# CTRL_MODULE_CORE register map
Vendor: Texas Instruments
Registers are 32-bit, access per field, reset 0x0 unless marked. A register's access mark holds for its fields unless they carry their own. Offsets are as the file gives them; [hi:lo] are bit positions; 'fields as' and 'values as' point back to an identical list.

## CTRL_MODULE_CORE (part 6 of 12)
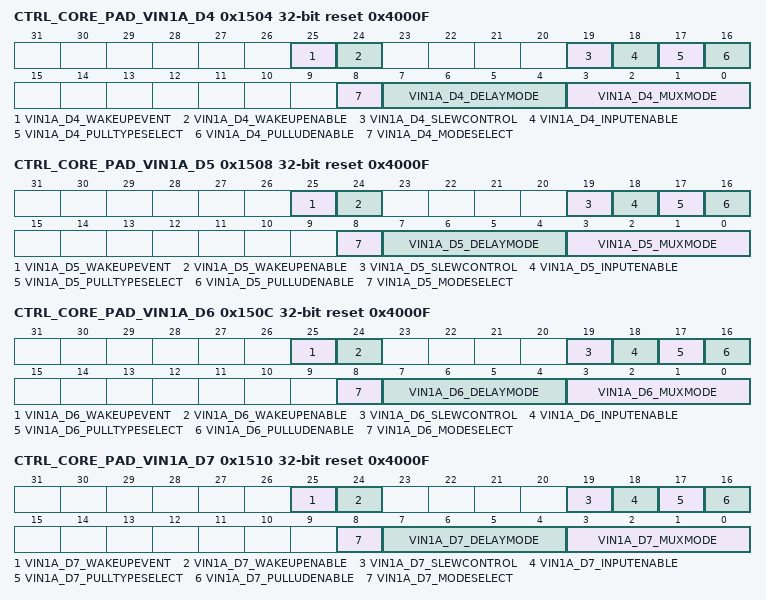
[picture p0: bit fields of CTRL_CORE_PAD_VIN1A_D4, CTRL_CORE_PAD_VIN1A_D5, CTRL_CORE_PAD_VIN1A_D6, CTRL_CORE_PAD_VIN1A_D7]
0x1504 CTRL_CORE_PAD_VIN1A_D4 reset 0x4000F
  [25] VIN1A_D4_WAKEUPEVENT ro
    0=NOWAKEUP (No wakeup event detected); 1=WAKEUP (Wakeup event detected)
  [24] VIN1A_D4_WAKEUPENABLE rw
    0=DISABLE (Wakeup is disabled); 1=ENABLE (Wakeup is enabled)
  [19] VIN1A_D4_SLEWCONTROL rw
    0=FAST_SLEW (Fast slew is selected); 1=SLOW_SLEW (Slow slew is selected)
  [18] VIN1A_D4_INPUTENABLE rw
    0=DISABLE (Receive mode is disabled); 1=ENABLE (Receive mode is enabled)
  [17] VIN1A_D4_PULLTYPESELECT rw
    0=PULL_DOWN (Pull Down is selected); 1=PULL_UP (Pull Up is selected)
  [16] VIN1A_D4_PULLUDENABLE rw
    0=ENABLE (Enables weak Pull Up/Down); 1=DISABLE (Disables weak Pull Up/Down)
  [8] VIN1A_D4_MODESELECT rw — Selects between the Default IO Timing Mode and a Virtual or Manual IO Timing Mode. Refer to the device Data Manual for definition of the required settings for a given mode of operation. When this bit is 0b1, a Virtual IO Timing Mode can be selected via the DELAYMODE field of this register, as described in, Virtual IO Timing Modes. Manual IO Timing Modes are selected via the procedure described in , Manual IO Timing Modes.
    0=MUX_MODE (Default IO Timing Mode is used); 1=DELAY_MODE (A Virtual or Manual IO Timing Mode is used)
  [7:4] VIN1A_D4_DELAYMODE rw — This bit field selects the Virtual Timing Mode used when the MODESELECT bit is set to 0b1. See, Virtual IO Timing Modes for details.
  [3:0] VIN1A_D4_MUXMODE rw
    0=VIN1A_D4; 3=VOUT3_D3; 4=VOUT3_D19; 10=EHRPWM1_SYNCI; 12=PR1_PRU0_GPI1; 13=PR1_PRU0_GPO1; 14=GPIO3_8; 15=DRIVER OFF
0x1508 CTRL_CORE_PAD_VIN1A_D5 reset 0x4000F
  [25] VIN1A_D5_WAKEUPEVENT ro
    values as CTRL_CORE_PAD_VIN1A_D4.VIN1A_D4_WAKEUPEVENT
  [24] VIN1A_D5_WAKEUPENABLE rw
    0=DISABLE (Wakeup is disabled); 1=ENABLE (Wakeup is enabled)
  [19] VIN1A_D5_SLEWCONTROL rw
    values as CTRL_CORE_PAD_VIN1A_D4.VIN1A_D4_SLEWCONTROL
  [18] VIN1A_D5_INPUTENABLE rw
    values as CTRL_CORE_PAD_VIN1A_D4.VIN1A_D4_INPUTENABLE
  [17] VIN1A_D5_PULLTYPESELECT rw
    values as CTRL_CORE_PAD_VIN1A_D4.VIN1A_D4_PULLTYPESELECT
  [16] VIN1A_D5_PULLUDENABLE rw
    values as CTRL_CORE_PAD_VIN1A_D4.VIN1A_D4_PULLUDENABLE
  [8] VIN1A_D5_MODESELECT rw — Selects between the Default IO Timing Mode and a Virtual or Manual IO Timing Mode. Refer to the device Data Manual for definition of the required settings for a given mode of operation. When this bit is 0b1, a Virtual IO Timing Mode can be selected via the DELAYMODE field of this register, as described in, Virtual IO Timing Modes. Manual IO Timing Modes are selected via the procedure described in , Manual IO Timing Modes.
    values as CTRL_CORE_PAD_VIN1A_D4.VIN1A_D4_MODESELECT
  [7:4] VIN1A_D5_DELAYMODE rw — This bit field selects the Virtual Timing Mode used when the MODESELECT bit is set to 0b1. See, Virtual IO Timing Modes for details.
  [3:0] VIN1A_D5_MUXMODE rw
    0=VIN1A_D5; 3=VOUT3_D2; 4=VOUT3_D18; 10=EHRPWM1_SYNCO; 12=PR1_PRU0_GPI2; 13=PR1_PRU0_GPO2; 14=GPIO3_9; 15=DRIVER OFF
0x150C CTRL_CORE_PAD_VIN1A_D6 reset 0x4000F
  [25] VIN1A_D6_WAKEUPEVENT ro
    values as CTRL_CORE_PAD_VIN1A_D4.VIN1A_D4_WAKEUPEVENT
  [24] VIN1A_D6_WAKEUPENABLE rw
    0=DISABLE (Wakeup is disabled); 1=ENABLE (Wakeup is enabled)
  [19] VIN1A_D6_SLEWCONTROL rw
    values as CTRL_CORE_PAD_VIN1A_D4.VIN1A_D4_SLEWCONTROL
  [18] VIN1A_D6_INPUTENABLE rw
    values as CTRL_CORE_PAD_VIN1A_D4.VIN1A_D4_INPUTENABLE
  [17] VIN1A_D6_PULLTYPESELECT rw
    values as CTRL_CORE_PAD_VIN1A_D4.VIN1A_D4_PULLTYPESELECT
  [16] VIN1A_D6_PULLUDENABLE rw
    values as CTRL_CORE_PAD_VIN1A_D4.VIN1A_D4_PULLUDENABLE
  [8] VIN1A_D6_MODESELECT rw — Selects between the Default IO Timing Mode and a Virtual or Manual IO Timing Mode. Refer to the device Data Manual for definition of the required settings for a given mode of operation. When this bit is 0b1, a Virtual IO Timing Mode can be selected via the DELAYMODE field of this register, as described in, Virtual IO Timing Modes. Manual IO Timing Modes are selected via the procedure described in , Manual IO Timing Modes.
    values as CTRL_CORE_PAD_VIN1A_D4.VIN1A_D4_MODESELECT
  [7:4] VIN1A_D6_DELAYMODE rw — This bit field selects the Virtual Timing Mode used when the MODESELECT bit is set to 0b1. See, Virtual IO Timing Modes for details.
  [3:0] VIN1A_D6_MUXMODE rw
    0=VIN1A_D6; 3=VOUT3_D1; 4=VOUT3_D17; 10=EQEP2A_IN; 12=PR1_PRU0_GPI3; 13=PR1_PRU0_GPO3; 14=GPIO3_10; 15=DRIVER OFF
0x1510 CTRL_CORE_PAD_VIN1A_D7 reset 0x4000F
  [25] VIN1A_D7_WAKEUPEVENT ro
    values as CTRL_CORE_PAD_VIN1A_D4.VIN1A_D4_WAKEUPEVENT
  [24] VIN1A_D7_WAKEUPENABLE rw
    0=DISABLE (Wakeup is disabled); 1=ENABLE (Wakeup is enabled)
  [19] VIN1A_D7_SLEWCONTROL rw
    values as CTRL_CORE_PAD_VIN1A_D4.VIN1A_D4_SLEWCONTROL
  [18] VIN1A_D7_INPUTENABLE rw
    values as CTRL_CORE_PAD_VIN1A_D4.VIN1A_D4_INPUTENABLE
  [17] VIN1A_D7_PULLTYPESELECT rw
    values as CTRL_CORE_PAD_VIN1A_D4.VIN1A_D4_PULLTYPESELECT
  [16] VIN1A_D7_PULLUDENABLE rw
    values as CTRL_CORE_PAD_VIN1A_D4.VIN1A_D4_PULLUDENABLE
  [8] VIN1A_D7_MODESELECT rw — Selects between the Default IO Timing Mode and a Virtual or Manual IO Timing Mode. Refer to the device Data Manual for definition of the required settings for a given mode of operation. When this bit is 0b1, a Virtual IO Timing Mode can be selected via the DELAYMODE field of this register, as described in, Virtual IO Timing Modes. Manual IO Timing Modes are selected via the procedure described in , Manual IO Timing Modes.
    values as CTRL_CORE_PAD_VIN1A_D4.VIN1A_D4_MODESELECT
  [7:4] VIN1A_D7_DELAYMODE rw — This bit field selects the Virtual Timing Mode used when the MODESELECT bit is set to 0b1. See, Virtual IO Timing Modes for details.
  [3:0] VIN1A_D7_MUXMODE rw
    0=VIN1A_D7; 3=VOUT3_D0; 4=VOUT3_D16; 10=EQEP2B_IN; 12=PR1_PRU0_GPI4; 13=PR1_PRU0_GPO4; 14=GPIO3_11; 15=DRIVER OFF
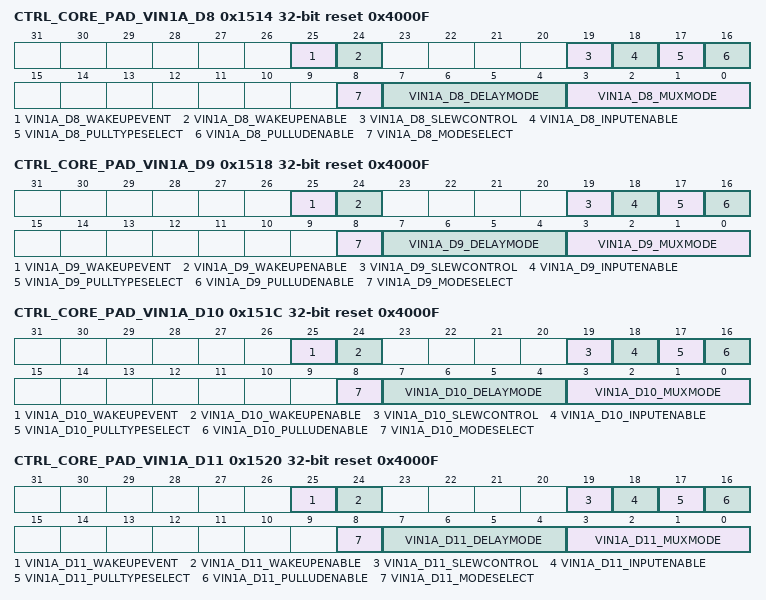
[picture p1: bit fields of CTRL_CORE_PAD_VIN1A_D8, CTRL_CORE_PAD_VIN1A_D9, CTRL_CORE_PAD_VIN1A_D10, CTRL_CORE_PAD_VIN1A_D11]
0x1514 CTRL_CORE_PAD_VIN1A_D8 reset 0x4000F
  [25] VIN1A_D8_WAKEUPEVENT ro
    values as CTRL_CORE_PAD_VIN1A_D4.VIN1A_D4_WAKEUPEVENT
  [24] VIN1A_D8_WAKEUPENABLE rw
    0=DISABLE (Wakeup is disabled); 1=ENABLE (Wakeup is enabled)
  [19] VIN1A_D8_SLEWCONTROL rw
    values as CTRL_CORE_PAD_VIN1A_D4.VIN1A_D4_SLEWCONTROL
  [18] VIN1A_D8_INPUTENABLE rw
    values as CTRL_CORE_PAD_VIN1A_D4.VIN1A_D4_INPUTENABLE
  [17] VIN1A_D8_PULLTYPESELECT rw
    values as CTRL_CORE_PAD_VIN1A_D4.VIN1A_D4_PULLTYPESELECT
  [16] VIN1A_D8_PULLUDENABLE rw
    values as CTRL_CORE_PAD_VIN1A_D4.VIN1A_D4_PULLUDENABLE
  [8] VIN1A_D8_MODESELECT rw — Selects between the Default IO Timing Mode and a Virtual or Manual IO Timing Mode. Refer to the device Data Manual for definition of the required settings for a given mode of operation. When this bit is 0b1, a Virtual IO Timing Mode can be selected via the DELAYMODE field of this register, as described in, Virtual IO Timing Modes. Manual IO Timing Modes are selected via the procedure described in , Manual IO Timing Modes.
    values as CTRL_CORE_PAD_VIN1A_D4.VIN1A_D4_MODESELECT
  [7:4] VIN1A_D8_DELAYMODE rw — This bit field selects the Virtual Timing Mode used when the MODESELECT bit is set to 0b1. See, Virtual IO Timing Modes for details.
  [3:0] VIN1A_D8_MUXMODE rw
    0=VIN1A_D8; 1=VIN1B_D7; 4=VOUT3_D15; 9=KBD_ROW2; 10=EQEP2_INDEX; 12=PR1_PRU0_GPI5; 13=PR1_PRU0_GPO5; 14=GPIO3_12; 15=DRIVER OFF
0x1518 CTRL_CORE_PAD_VIN1A_D9 reset 0x4000F
  [25] VIN1A_D9_WAKEUPEVENT ro
    values as CTRL_CORE_PAD_VIN1A_D4.VIN1A_D4_WAKEUPEVENT
  [24] VIN1A_D9_WAKEUPENABLE rw
    0=DISABLE (Wakeup is disabled); 1=ENABLE (Wakeup is enabled)
  [19] VIN1A_D9_SLEWCONTROL rw
    values as CTRL_CORE_PAD_VIN1A_D4.VIN1A_D4_SLEWCONTROL
  [18] VIN1A_D9_INPUTENABLE rw
    values as CTRL_CORE_PAD_VIN1A_D4.VIN1A_D4_INPUTENABLE
  [17] VIN1A_D9_PULLTYPESELECT rw
    values as CTRL_CORE_PAD_VIN1A_D4.VIN1A_D4_PULLTYPESELECT
  [16] VIN1A_D9_PULLUDENABLE rw
    values as CTRL_CORE_PAD_VIN1A_D4.VIN1A_D4_PULLUDENABLE
  [8] VIN1A_D9_MODESELECT rw — Selects between the Default IO Timing Mode and a Virtual or Manual IO Timing Mode. Refer to the device Data Manual for definition of the required settings for a given mode of operation. When this bit is 0b1, a Virtual IO Timing Mode can be selected via the DELAYMODE field of this register, as described in, Virtual IO Timing Modes. Manual IO Timing Modes are selected via the procedure described in , Manual IO Timing Modes.
    values as CTRL_CORE_PAD_VIN1A_D4.VIN1A_D4_MODESELECT
  [7:4] VIN1A_D9_DELAYMODE rw — This bit field selects the Virtual Timing Mode used when the MODESELECT bit is set to 0b1. See, Virtual IO Timing Modes for details.
  [3:0] VIN1A_D9_MUXMODE rw
    0=VIN1A_D9; 1=VIN1B_D6; 4=VOUT3_D14; 9=KBD_ROW3; 10=EQEP2_STROBE; 12=PR1_PRU0_GPI6; 13=PR1_PRU0_GPO6; 14=GPIO3_13; 15=DRIVER OFF
0x151C CTRL_CORE_PAD_VIN1A_D10 reset 0x4000F
  [25] VIN1A_D10_WAKEUPEVENT ro
    values as CTRL_CORE_PAD_VIN1A_D4.VIN1A_D4_WAKEUPEVENT
  [24] VIN1A_D10_WAKEUPENABLE rw
    0=DISABLE (Wakeup is disabled); 1=ENABLE (Wakeup is enabled)
  [19] VIN1A_D10_SLEWCONTROL rw
    values as CTRL_CORE_PAD_VIN1A_D4.VIN1A_D4_SLEWCONTROL
  [18] VIN1A_D10_INPUTENABLE rw
    values as CTRL_CORE_PAD_VIN1A_D4.VIN1A_D4_INPUTENABLE
  [17] VIN1A_D10_PULLTYPESELECT rw
    values as CTRL_CORE_PAD_VIN1A_D4.VIN1A_D4_PULLTYPESELECT
  [16] VIN1A_D10_PULLUDENABLE rw
    values as CTRL_CORE_PAD_VIN1A_D4.VIN1A_D4_PULLUDENABLE
  [8] VIN1A_D10_MODESELECT rw — Selects between the Default IO Timing Mode and a Virtual or Manual IO Timing Mode. Refer to the device Data Manual for definition of the required settings for a given mode of operation. When this bit is 0b1, a Virtual IO Timing Mode can be selected via the DELAYMODE field of this register, as described in, Virtual IO Timing Modes. Manual IO Timing Modes are selected via the procedure described in , Manual IO Timing Modes.
    values as CTRL_CORE_PAD_VIN1A_D4.VIN1A_D4_MODESELECT
  [7:4] VIN1A_D10_DELAYMODE rw — This bit field selects the Virtual Timing Mode used when the MODESELECT bit is set to 0b1. See, Virtual IO Timing Modes for details.
  [3:0] VIN1A_D10_MUXMODE rw
    0=VIN1A_D10; 1=VIN1B_D5; 4=VOUT3_D13; 9=KBD_ROW4; 10=PR1_EDC_LATCH0_IN; 12=PR1_PRU0_GPI7; 13=PR1_PRU0_GPO7; 14=GPIO3_14; 15=DRIVER OFF
0x1520 CTRL_CORE_PAD_VIN1A_D11 reset 0x4000F
  [25] VIN1A_D11_WAKEUPEVENT ro
    values as CTRL_CORE_PAD_VIN1A_D4.VIN1A_D4_WAKEUPEVENT
  [24] VIN1A_D11_WAKEUPENABLE rw
    0=DISABLE (Wakeup is disabled); 1=ENABLE (Wakeup is enabled)
  [19] VIN1A_D11_SLEWCONTROL rw
    values as CTRL_CORE_PAD_VIN1A_D4.VIN1A_D4_SLEWCONTROL
  [18] VIN1A_D11_INPUTENABLE rw
    values as CTRL_CORE_PAD_VIN1A_D4.VIN1A_D4_INPUTENABLE
  [17] VIN1A_D11_PULLTYPESELECT rw
    values as CTRL_CORE_PAD_VIN1A_D4.VIN1A_D4_PULLTYPESELECT
  [16] VIN1A_D11_PULLUDENABLE rw
    values as CTRL_CORE_PAD_VIN1A_D4.VIN1A_D4_PULLUDENABLE
  [8] VIN1A_D11_MODESELECT rw — Selects between the Default IO Timing Mode and a Virtual or Manual IO Timing Mode. Refer to the device Data Manual for definition of the required settings for a given mode of operation. When this bit is 0b1, a Virtual IO Timing Mode can be selected via the DELAYMODE field of this register, as described in, Virtual IO Timing Modes. Manual IO Timing Modes are selected via the procedure described in , Manual IO Timing Modes.
    values as CTRL_CORE_PAD_VIN1A_D4.VIN1A_D4_MODESELECT
  [7:4] VIN1A_D11_DELAYMODE rw — This bit field selects the Virtual Timing Mode used when the MODESELECT bit is set to 0b1. See, Virtual IO Timing Modes for details.
  [3:0] VIN1A_D11_MUXMODE rw
    0=VIN1A_D11; 1=VIN1B_D4; 4=VOUT3_D12; 5=GPMC_A23; 9=KBD_ROW5; 10=PR1_EDC_LATCH1_IN; 12=PR1_PRU0_GPI8; 13=PR1_PRU0_GPO8; 14=GPIO3_15; 15=DRIVER OFF
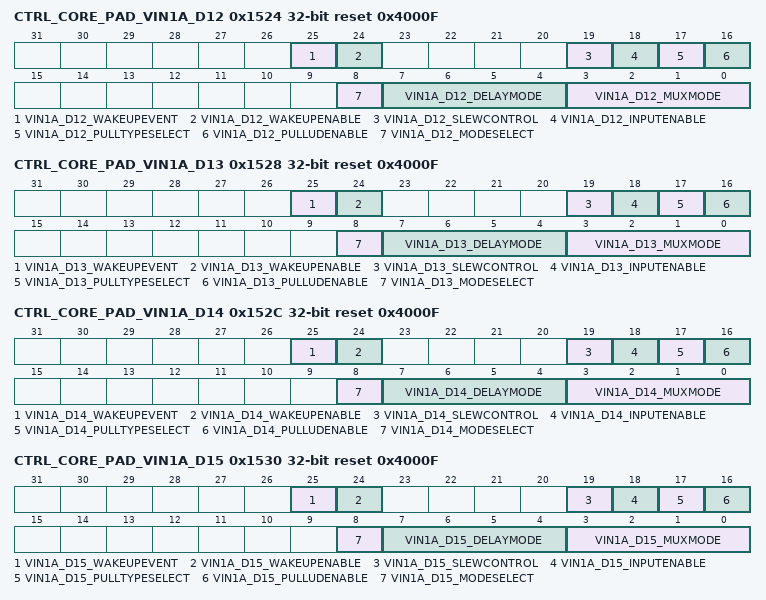
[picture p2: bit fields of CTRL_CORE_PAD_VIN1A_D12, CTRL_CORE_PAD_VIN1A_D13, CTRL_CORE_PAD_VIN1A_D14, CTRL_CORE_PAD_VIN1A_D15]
0x1524 CTRL_CORE_PAD_VIN1A_D12 reset 0x4000F
  [25] VIN1A_D12_WAKEUPEVENT ro
    values as CTRL_CORE_PAD_VIN1A_D4.VIN1A_D4_WAKEUPEVENT
  [24] VIN1A_D12_WAKEUPENABLE rw
    0=DISABLE (Wakeup is disabled); 1=ENABLE (Wakeup is enabled)
  [19] VIN1A_D12_SLEWCONTROL rw
    values as CTRL_CORE_PAD_VIN1A_D4.VIN1A_D4_SLEWCONTROL
  [18] VIN1A_D12_INPUTENABLE rw
    values as CTRL_CORE_PAD_VIN1A_D4.VIN1A_D4_INPUTENABLE
  [17] VIN1A_D12_PULLTYPESELECT rw
    values as CTRL_CORE_PAD_VIN1A_D4.VIN1A_D4_PULLTYPESELECT
  [16] VIN1A_D12_PULLUDENABLE rw
    values as CTRL_CORE_PAD_VIN1A_D4.VIN1A_D4_PULLUDENABLE
  [8] VIN1A_D12_MODESELECT rw — Selects between the Default IO Timing Mode and a Virtual or Manual IO Timing Mode. Refer to the device Data Manual for definition of the required settings for a given mode of operation. When this bit is 0b1, a Virtual IO Timing Mode can be selected via the DELAYMODE field of this register, as described in, Virtual IO Timing Modes. Manual IO Timing Modes are selected via the procedure described in , Manual IO Timing Modes.
    values as CTRL_CORE_PAD_VIN1A_D4.VIN1A_D4_MODESELECT
  [7:4] VIN1A_D12_DELAYMODE rw — This bit field selects the Virtual Timing Mode used when the MODESELECT bit is set to 0b1. See, Virtual IO Timing Modes for details.
  [3:0] VIN1A_D12_MUXMODE rw
    0=VIN1A_D12; 1=VIN1B_D3; 4=VOUT3_D11; 5=GPMC_A24; 9=KBD_ROW6; 10=PR1_EDC_SYNC0_OUT; 12=PR1_PRU0_GPI9; 13=PR1_PRU0_GPO9; 14=GPIO3_16; 15=DRIVER OFF
0x1528 CTRL_CORE_PAD_VIN1A_D13 reset 0x4000F
  [25] VIN1A_D13_WAKEUPEVENT ro
    values as CTRL_CORE_PAD_VIN1A_D4.VIN1A_D4_WAKEUPEVENT
  [24] VIN1A_D13_WAKEUPENABLE rw
    0=DISABLE (Wakeup is disabled); 1=ENABLE (Wakeup is enabled)
  [19] VIN1A_D13_SLEWCONTROL rw
    values as CTRL_CORE_PAD_VIN1A_D4.VIN1A_D4_SLEWCONTROL
  [18] VIN1A_D13_INPUTENABLE rw
    values as CTRL_CORE_PAD_VIN1A_D4.VIN1A_D4_INPUTENABLE
  [17] VIN1A_D13_PULLTYPESELECT rw
    values as CTRL_CORE_PAD_VIN1A_D4.VIN1A_D4_PULLTYPESELECT
  [16] VIN1A_D13_PULLUDENABLE rw
    values as CTRL_CORE_PAD_VIN1A_D4.VIN1A_D4_PULLUDENABLE
  [8] VIN1A_D13_MODESELECT rw — Selects between the Default IO Timing Mode and a Virtual or Manual IO Timing Mode. Refer to the device Data Manual for definition of the required settings for a given mode of operation. When this bit is 0b1, a Virtual IO Timing Mode can be selected via the DELAYMODE field of this register, as described in, Virtual IO Timing Modes. Manual IO Timing Modes are selected via the procedure described in , Manual IO Timing Modes.
    values as CTRL_CORE_PAD_VIN1A_D4.VIN1A_D4_MODESELECT
  [7:4] VIN1A_D13_DELAYMODE rw — This bit field selects the Virtual Timing Mode used when the MODESELECT bit is set to 0b1. See, Virtual IO Timing Modes for details.
  [3:0] VIN1A_D13_MUXMODE rw
    0=VIN1A_D13; 1=VIN1B_D2; 4=VOUT3_D10; 5=GPMC_A25; 9=KBD_ROW7; 10=PR1_EDC_SYNC1_OUT; 12=PR1_PRU0_GPI10; 13=PR1_PRU0_GPO10; 14=GPIO3_17; 15=DRIVER OFF
0x152C CTRL_CORE_PAD_VIN1A_D14 reset 0x4000F
  [25] VIN1A_D14_WAKEUPEVENT ro
    values as CTRL_CORE_PAD_VIN1A_D4.VIN1A_D4_WAKEUPEVENT
  [24] VIN1A_D14_WAKEUPENABLE rw
    0=DISABLE (Wakeup is disabled); 1=ENABLE (Wakeup is enabled)
  [19] VIN1A_D14_SLEWCONTROL rw
    values as CTRL_CORE_PAD_VIN1A_D4.VIN1A_D4_SLEWCONTROL
  [18] VIN1A_D14_INPUTENABLE rw
    values as CTRL_CORE_PAD_VIN1A_D4.VIN1A_D4_INPUTENABLE
  [17] VIN1A_D14_PULLTYPESELECT rw
    values as CTRL_CORE_PAD_VIN1A_D4.VIN1A_D4_PULLTYPESELECT
  [16] VIN1A_D14_PULLUDENABLE rw
    values as CTRL_CORE_PAD_VIN1A_D4.VIN1A_D4_PULLUDENABLE
  [8] VIN1A_D14_MODESELECT rw — Selects between the Default IO Timing Mode and a Virtual or Manual IO Timing Mode. Refer to the device Data Manual for definition of the required settings for a given mode of operation. When this bit is 0b1, a Virtual IO Timing Mode can be selected via the DELAYMODE field of this register, as described in, Virtual IO Timing Modes. Manual IO Timing Modes are selected via the procedure described in , Manual IO Timing Modes.
    values as CTRL_CORE_PAD_VIN1A_D4.VIN1A_D4_MODESELECT
  [7:4] VIN1A_D14_DELAYMODE rw — This bit field selects the Virtual Timing Mode used when the MODESELECT bit is set to 0b1. See, Virtual IO Timing Modes for details.
  [3:0] VIN1A_D14_MUXMODE rw
    0=VIN1A_D14; 1=VIN1B_D1; 4=VOUT3_D9; 5=GPMC_A26; 9=KBD_ROW8; 10=PR1_EDIO_LATCH_IN; 12=PR1_PRU0_GPI11; 13=PR1_PRU0_GPO11; 14=GPIO3_18; 15=DRIVER OFF
0x1530 CTRL_CORE_PAD_VIN1A_D15 reset 0x4000F
  [25] VIN1A_D15_WAKEUPEVENT ro
    values as CTRL_CORE_PAD_VIN1A_D4.VIN1A_D4_WAKEUPEVENT
  [24] VIN1A_D15_WAKEUPENABLE rw
    0=DISABLE (Wakeup is disabled); 1=ENABLE (Wakeup is enabled)
  [19] VIN1A_D15_SLEWCONTROL rw
    values as CTRL_CORE_PAD_VIN1A_D4.VIN1A_D4_SLEWCONTROL
  [18] VIN1A_D15_INPUTENABLE rw
    values as CTRL_CORE_PAD_VIN1A_D4.VIN1A_D4_INPUTENABLE
  [17] VIN1A_D15_PULLTYPESELECT rw
    values as CTRL_CORE_PAD_VIN1A_D4.VIN1A_D4_PULLTYPESELECT
  [16] VIN1A_D15_PULLUDENABLE rw
    values as CTRL_CORE_PAD_VIN1A_D4.VIN1A_D4_PULLUDENABLE
  [8] VIN1A_D15_MODESELECT rw — Selects between the Default IO Timing Mode and a Virtual or Manual IO Timing Mode. Refer to the device Data Manual for definition of the required settings for a given mode of operation. When this bit is 0b1, a Virtual IO Timing Mode can be selected via the DELAYMODE field of this register, as described in, Virtual IO Timing Modes. Manual IO Timing Modes are selected via the procedure described in , Manual IO Timing Modes.
    values as CTRL_CORE_PAD_VIN1A_D4.VIN1A_D4_MODESELECT
  [7:4] VIN1A_D15_DELAYMODE rw — This bit field selects the Virtual Timing Mode used when the MODESELECT bit is set to 0b1. See, Virtual IO Timing Modes for details.
  [3:0] VIN1A_D15_MUXMODE rw
    0=VIN1A_D15; 1=VIN1B_D0; 4=VOUT3_D8; 5=GPMC_A27; 9=KBD_COL0; 10=PR1_EDIO_SOF; 12=PR1_PRU0_GPI12; 13=PR1_PRU0_GPO12; 14=GPIO3_19; 15=DRIVER OFF
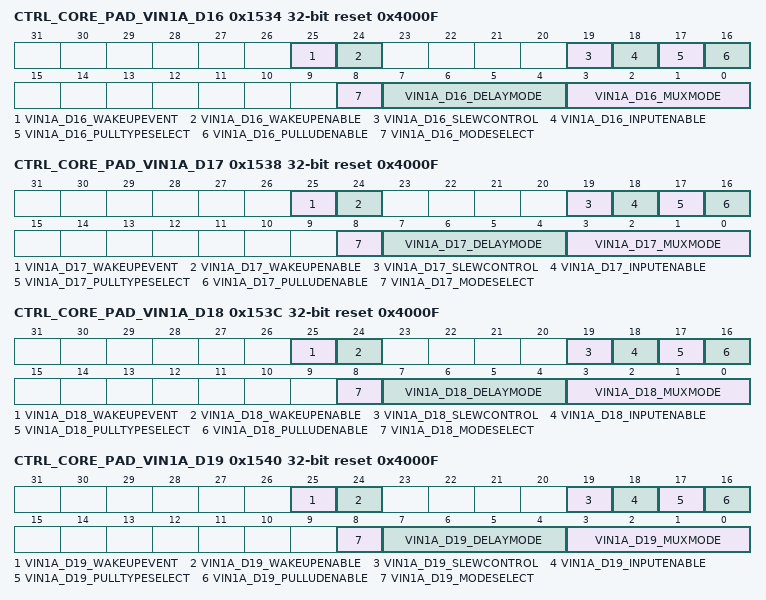
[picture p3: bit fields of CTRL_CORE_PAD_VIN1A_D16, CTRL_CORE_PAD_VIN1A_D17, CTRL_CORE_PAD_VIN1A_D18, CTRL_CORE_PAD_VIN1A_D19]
0x1534 CTRL_CORE_PAD_VIN1A_D16 reset 0x4000F
  [25] VIN1A_D16_WAKEUPEVENT ro
    values as CTRL_CORE_PAD_VIN1A_D4.VIN1A_D4_WAKEUPEVENT
  [24] VIN1A_D16_WAKEUPENABLE rw
    0=DISABLE (Wakeup is disabled); 1=ENABLE (Wakeup is enabled)
  [19] VIN1A_D16_SLEWCONTROL rw
    values as CTRL_CORE_PAD_VIN1A_D4.VIN1A_D4_SLEWCONTROL
  [18] VIN1A_D16_INPUTENABLE rw
    values as CTRL_CORE_PAD_VIN1A_D4.VIN1A_D4_INPUTENABLE
  [17] VIN1A_D16_PULLTYPESELECT rw
    values as CTRL_CORE_PAD_VIN1A_D4.VIN1A_D4_PULLTYPESELECT
  [16] VIN1A_D16_PULLUDENABLE rw
    values as CTRL_CORE_PAD_VIN1A_D4.VIN1A_D4_PULLUDENABLE
  [8] VIN1A_D16_MODESELECT rw — Selects between the Default IO Timing Mode and a Virtual or Manual IO Timing Mode. Refer to the device Data Manual for definition of the required settings for a given mode of operation. When this bit is 0b1, a Virtual IO Timing Mode can be selected via the DELAYMODE field of this register, as described in, Virtual IO Timing Modes. Manual IO Timing Modes are selected via the procedure described in , Manual IO Timing Modes.
    values as CTRL_CORE_PAD_VIN1A_D4.VIN1A_D4_MODESELECT
  [7:4] VIN1A_D16_DELAYMODE rw — This bit field selects the Virtual Timing Mode used when the MODESELECT bit is set to 0b1. See, Virtual IO Timing Modes for details.
  [3:0] VIN1A_D16_MUXMODE rw
    0=VIN1A_D16; 1=VIN1B_D7; 4=VOUT3_D7; 6=VIN3A_D0; 9=KBD_COL1; 10=PR1_EDIO_DATA_IN0; 11=PR1_EDIO_DATA_OUT0; 12=PR1_PRU0_GPI13; 13=PR1_PRU0_GPO13; 14=GPIO3_20; 15=DRIVER OFF
0x1538 CTRL_CORE_PAD_VIN1A_D17 reset 0x4000F
  [25] VIN1A_D17_WAKEUPEVENT ro
    values as CTRL_CORE_PAD_VIN1A_D4.VIN1A_D4_WAKEUPEVENT
  [24] VIN1A_D17_WAKEUPENABLE rw
    0=DISABLE (Wakeup is disabled); 1=ENABLE (Wakeup is enabled)
  [19] VIN1A_D17_SLEWCONTROL rw
    values as CTRL_CORE_PAD_VIN1A_D4.VIN1A_D4_SLEWCONTROL
  [18] VIN1A_D17_INPUTENABLE rw
    values as CTRL_CORE_PAD_VIN1A_D4.VIN1A_D4_INPUTENABLE
  [17] VIN1A_D17_PULLTYPESELECT rw
    values as CTRL_CORE_PAD_VIN1A_D4.VIN1A_D4_PULLTYPESELECT
  [16] VIN1A_D17_PULLUDENABLE rw
    values as CTRL_CORE_PAD_VIN1A_D4.VIN1A_D4_PULLUDENABLE
  [8] VIN1A_D17_MODESELECT rw — Selects between the Default IO Timing Mode and a Virtual or Manual IO Timing Mode. Refer to the device Data Manual for definition of the required settings for a given mode of operation. When this bit is 0b1, a Virtual IO Timing Mode can be selected via the DELAYMODE field of this register, as described in, Virtual IO Timing Modes. Manual IO Timing Modes are selected via the procedure described in , Manual IO Timing Modes.
    values as CTRL_CORE_PAD_VIN1A_D4.VIN1A_D4_MODESELECT
  [7:4] VIN1A_D17_DELAYMODE rw — This bit field selects the Virtual Timing Mode used when the MODESELECT bit is set to 0b1. See, Virtual IO Timing Modes for details.
  [3:0] VIN1A_D17_MUXMODE rw
    0=VIN1A_D17; 1=VIN1B_D6; 4=VOUT3_D6; 6=VIN3A_D1; 9=KBD_COL2; 10=PR1_EDIO_DATA_IN1; 11=PR1_EDIO_DATA_OUT1; 12=PR1_PRU0_GPI14; 13=PR1_PRU0_GPO14; 14=GPIO3_21; 15=DRIVER OFF
0x153C CTRL_CORE_PAD_VIN1A_D18 reset 0x4000F
  [25] VIN1A_D18_WAKEUPEVENT ro
    values as CTRL_CORE_PAD_VIN1A_D4.VIN1A_D4_WAKEUPEVENT
  [24] VIN1A_D18_WAKEUPENABLE rw
    0=DISABLE (Wakeup is disabled); 1=ENABLE (Wakeup is enabled)
  [19] VIN1A_D18_SLEWCONTROL rw
    values as CTRL_CORE_PAD_VIN1A_D4.VIN1A_D4_SLEWCONTROL
  [18] VIN1A_D18_INPUTENABLE rw
    values as CTRL_CORE_PAD_VIN1A_D4.VIN1A_D4_INPUTENABLE
  [17] VIN1A_D18_PULLTYPESELECT rw
    values as CTRL_CORE_PAD_VIN1A_D4.VIN1A_D4_PULLTYPESELECT
  [16] VIN1A_D18_PULLUDENABLE rw
    values as CTRL_CORE_PAD_VIN1A_D4.VIN1A_D4_PULLUDENABLE
  [8] VIN1A_D18_MODESELECT rw — Selects between the Default IO Timing Mode and a Virtual or Manual IO Timing Mode. Refer to the device Data Manual for definition of the required settings for a given mode of operation. When this bit is 0b1, a Virtual IO Timing Mode can be selected via the DELAYMODE field of this register, as described in, Virtual IO Timing Modes. Manual IO Timing Modes are selected via the procedure described in , Manual IO Timing Modes.
    values as CTRL_CORE_PAD_VIN1A_D4.VIN1A_D4_MODESELECT
  [7:4] VIN1A_D18_DELAYMODE rw — This bit field selects the Virtual Timing Mode used when the MODESELECT bit is set to 0b1. See, Virtual IO Timing Modes for details.
  [3:0] VIN1A_D18_MUXMODE rw
    0=VIN1A_D18; 1=VIN1B_D5; 4=VOUT3_D5; 6=VIN3A_D2; 9=KBD_COL3; 10=PR1_EDIO_DATA_IN2; 11=PR1_EDIO_DATA_OUT2; 12=PR1_PRU0_GPI15; 13=PR1_PRU0_GPO15; 14=GPIO3_22; 15=DRIVER OFF
0x1540 CTRL_CORE_PAD_VIN1A_D19 reset 0x4000F
  [25] VIN1A_D19_WAKEUPEVENT ro
    values as CTRL_CORE_PAD_VIN1A_D4.VIN1A_D4_WAKEUPEVENT
  [24] VIN1A_D19_WAKEUPENABLE rw
    0=DISABLE (Wakeup is disabled); 1=ENABLE (Wakeup is enabled)
  [19] VIN1A_D19_SLEWCONTROL rw
    values as CTRL_CORE_PAD_VIN1A_D4.VIN1A_D4_SLEWCONTROL
  [18] VIN1A_D19_INPUTENABLE rw
    values as CTRL_CORE_PAD_VIN1A_D4.VIN1A_D4_INPUTENABLE
  [17] VIN1A_D19_PULLTYPESELECT rw
    values as CTRL_CORE_PAD_VIN1A_D4.VIN1A_D4_PULLTYPESELECT
  [16] VIN1A_D19_PULLUDENABLE rw
    values as CTRL_CORE_PAD_VIN1A_D4.VIN1A_D4_PULLUDENABLE
  [8] VIN1A_D19_MODESELECT rw — Selects between the Default IO Timing Mode and a Virtual or Manual IO Timing Mode. Refer to the device Data Manual for definition of the required settings for a given mode of operation. When this bit is 0b1, a Virtual IO Timing Mode can be selected via the DELAYMODE field of this register, as described in, Virtual IO Timing Modes. Manual IO Timing Modes are selected via the procedure described in , Manual IO Timing Modes.
    values as CTRL_CORE_PAD_VIN1A_D4.VIN1A_D4_MODESELECT
  [7:4] VIN1A_D19_DELAYMODE rw — This bit field selects the Virtual Timing Mode used when the MODESELECT bit is set to 0b1. See, Virtual IO Timing Modes for details.
  [3:0] VIN1A_D19_MUXMODE rw
    0=VIN1A_D19; 1=VIN1B_D4; 4=VOUT3_D4; 6=VIN3A_D3; 9=KBD_COL4; 10=PR1_EDIO_DATA_IN3; 11=PR1_EDIO_DATA_OUT3; 12=PR1_PRU0_GPI16; 13=PR1_PRU0_GPO16; 14=GPIO3_23; 15=DRIVER OFF
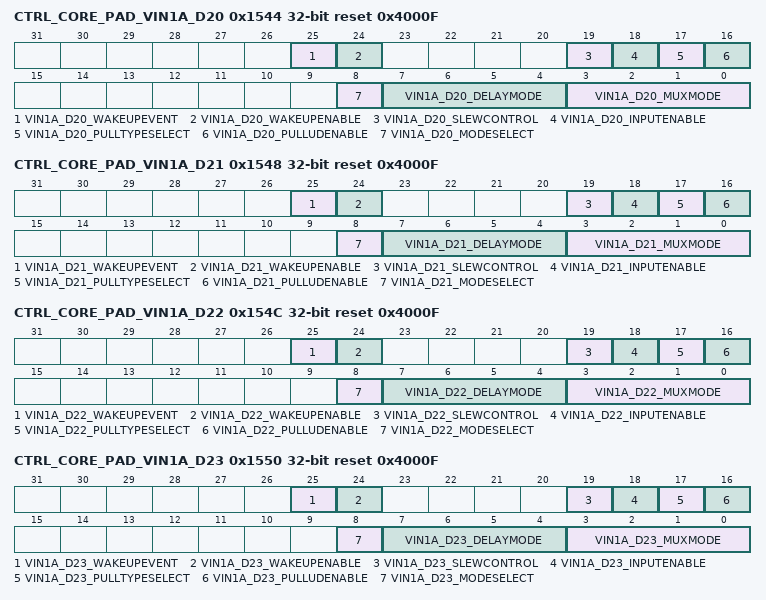
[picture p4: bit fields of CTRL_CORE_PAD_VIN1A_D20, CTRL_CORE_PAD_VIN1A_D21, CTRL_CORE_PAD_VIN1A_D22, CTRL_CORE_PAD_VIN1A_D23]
0x1544 CTRL_CORE_PAD_VIN1A_D20 reset 0x4000F
  [25] VIN1A_D20_WAKEUPEVENT ro
    values as CTRL_CORE_PAD_VIN1A_D4.VIN1A_D4_WAKEUPEVENT
  [24] VIN1A_D20_WAKEUPENABLE rw
    0=DISABLE (Wakeup is disabled); 1=ENABLE (Wakeup is enabled)
  [19] VIN1A_D20_SLEWCONTROL rw
    values as CTRL_CORE_PAD_VIN1A_D4.VIN1A_D4_SLEWCONTROL
  [18] VIN1A_D20_INPUTENABLE rw
    values as CTRL_CORE_PAD_VIN1A_D4.VIN1A_D4_INPUTENABLE
  [17] VIN1A_D20_PULLTYPESELECT rw
    values as CTRL_CORE_PAD_VIN1A_D4.VIN1A_D4_PULLTYPESELECT
  [16] VIN1A_D20_PULLUDENABLE rw
    values as CTRL_CORE_PAD_VIN1A_D4.VIN1A_D4_PULLUDENABLE
  [8] VIN1A_D20_MODESELECT rw — Selects between the Default IO Timing Mode and a Virtual or Manual IO Timing Mode. Refer to the device Data Manual for definition of the required settings for a given mode of operation. When this bit is 0b1, a Virtual IO Timing Mode can be selected via the DELAYMODE field of this register, as described in, Virtual IO Timing Modes. Manual IO Timing Modes are selected via the procedure described in , Manual IO Timing Modes.
    values as CTRL_CORE_PAD_VIN1A_D4.VIN1A_D4_MODESELECT
  [7:4] VIN1A_D20_DELAYMODE rw — This bit field selects the Virtual Timing Mode used when the MODESELECT bit is set to 0b1. See, Virtual IO Timing Modes for details.
  [3:0] VIN1A_D20_MUXMODE rw
    0=VIN1A_D20; 1=VIN1B_D3; 4=VOUT3_D3; 6=VIN3A_D4; 9=KBD_COL5; 10=PR1_EDIO_DATA_IN4; 11=PR1_EDIO_DATA_OUT4; 12=PR1_PRU0_GPI17; 13=PR1_PRU0_GPO17; 14=GPIO3_24; 15=DRIVER OFF
0x1548 CTRL_CORE_PAD_VIN1A_D21 reset 0x4000F
  [25] VIN1A_D21_WAKEUPEVENT ro
    values as CTRL_CORE_PAD_VIN1A_D4.VIN1A_D4_WAKEUPEVENT
  [24] VIN1A_D21_WAKEUPENABLE rw
    0=DISABLE (Wakeup is disabled); 1=ENABLE (Wakeup is enabled)
  [19] VIN1A_D21_SLEWCONTROL rw
    values as CTRL_CORE_PAD_VIN1A_D4.VIN1A_D4_SLEWCONTROL
  [18] VIN1A_D21_INPUTENABLE rw
    values as CTRL_CORE_PAD_VIN1A_D4.VIN1A_D4_INPUTENABLE
  [17] VIN1A_D21_PULLTYPESELECT rw
    values as CTRL_CORE_PAD_VIN1A_D4.VIN1A_D4_PULLTYPESELECT
  [16] VIN1A_D21_PULLUDENABLE rw
    values as CTRL_CORE_PAD_VIN1A_D4.VIN1A_D4_PULLUDENABLE
  [8] VIN1A_D21_MODESELECT rw — Selects between the Default IO Timing Mode and a Virtual or Manual IO Timing Mode. Refer to the device Data Manual for definition of the required settings for a given mode of operation. When this bit is 0b1, a Virtual IO Timing Mode can be selected via the DELAYMODE field of this register, as described in, Virtual IO Timing Modes. Manual IO Timing Modes are selected via the procedure described in , Manual IO Timing Modes.
    values as CTRL_CORE_PAD_VIN1A_D4.VIN1A_D4_MODESELECT
  [7:4] VIN1A_D21_DELAYMODE rw — This bit field selects the Virtual Timing Mode used when the MODESELECT bit is set to 0b1. See, Virtual IO Timing Modes for details.
  [3:0] VIN1A_D21_MUXMODE rw
    0=VIN1A_D21; 1=VIN1B_D2; 4=VOUT3_D2; 6=VIN3A_D5; 9=KBD_COL6; 10=PR1_EDIO_DATA_IN5; 11=PR1_EDIO_DATA_OUT5; 12=PR1_PRU0_GPI18; 13=PR1_PRU0_GPO18; 14=GPIO3_25; 15=DRIVER OFF
0x154C CTRL_CORE_PAD_VIN1A_D22 reset 0x4000F
  [25] VIN1A_D22_WAKEUPEVENT ro
    values as CTRL_CORE_PAD_VIN1A_D4.VIN1A_D4_WAKEUPEVENT
  [24] VIN1A_D22_WAKEUPENABLE rw
    0=DISABLE (Wakeup is disabled); 1=ENABLE (Wakeup is enabled)
  [19] VIN1A_D22_SLEWCONTROL rw
    values as CTRL_CORE_PAD_VIN1A_D4.VIN1A_D4_SLEWCONTROL
  [18] VIN1A_D22_INPUTENABLE rw
    values as CTRL_CORE_PAD_VIN1A_D4.VIN1A_D4_INPUTENABLE
  [17] VIN1A_D22_PULLTYPESELECT rw
    values as CTRL_CORE_PAD_VIN1A_D4.VIN1A_D4_PULLTYPESELECT
  [16] VIN1A_D22_PULLUDENABLE rw
    values as CTRL_CORE_PAD_VIN1A_D4.VIN1A_D4_PULLUDENABLE
  [8] VIN1A_D22_MODESELECT rw — Selects between the Default IO Timing Mode and a Virtual or Manual IO Timing Mode. Refer to the device Data Manual for definition of the required settings for a given mode of operation. When this bit is 0b1, a Virtual IO Timing Mode can be selected via the DELAYMODE field of this register, as described in, Virtual IO Timing Modes. Manual IO Timing Modes are selected via the procedure described in , Manual IO Timing Modes.
    values as CTRL_CORE_PAD_VIN1A_D4.VIN1A_D4_MODESELECT
  [7:4] VIN1A_D22_DELAYMODE rw — This bit field selects the Virtual Timing Mode used when the MODESELECT bit is set to 0b1. See, Virtual IO Timing Modes for details.
  [3:0] VIN1A_D22_MUXMODE rw
    0=VIN1A_D22; 1=VIN1B_D1; 4=VOUT3_D1; 6=VIN3A_D6; 9=KBD_COL7; 10=PR1_EDIO_DATA_IN6; 11=PR1_EDIO_DATA_OUT6; 12=PR1_PRU0_GPI19; 13=PR1_PRU0_GPO19; 14=GPIO3_26; 15=DRIVER OFF
0x1550 CTRL_CORE_PAD_VIN1A_D23 reset 0x4000F
  [25] VIN1A_D23_WAKEUPEVENT ro
    values as CTRL_CORE_PAD_VIN1A_D4.VIN1A_D4_WAKEUPEVENT
  [24] VIN1A_D23_WAKEUPENABLE rw
    0=DISABLE (Wakeup is disabled); 1=ENABLE (Wakeup is enabled)
  [19] VIN1A_D23_SLEWCONTROL rw
    values as CTRL_CORE_PAD_VIN1A_D4.VIN1A_D4_SLEWCONTROL
  [18] VIN1A_D23_INPUTENABLE rw
    values as CTRL_CORE_PAD_VIN1A_D4.VIN1A_D4_INPUTENABLE
  [17] VIN1A_D23_PULLTYPESELECT rw
    values as CTRL_CORE_PAD_VIN1A_D4.VIN1A_D4_PULLTYPESELECT
  [16] VIN1A_D23_PULLUDENABLE rw
    values as CTRL_CORE_PAD_VIN1A_D4.VIN1A_D4_PULLUDENABLE
  [8] VIN1A_D23_MODESELECT rw — Selects between the Default IO Timing Mode and a Virtual or Manual IO Timing Mode. Refer to the device Data Manual for definition of the required settings for a given mode of operation. When this bit is 0b1, a Virtual IO Timing Mode can be selected via the DELAYMODE field of this register, as described in, Virtual IO Timing Modes. Manual IO Timing Modes are selected via the procedure described in , Manual IO Timing Modes.
    values as CTRL_CORE_PAD_VIN1A_D4.VIN1A_D4_MODESELECT
  [7:4] VIN1A_D23_DELAYMODE rw — This bit field selects the Virtual Timing Mode used when the MODESELECT bit is set to 0b1. See, Virtual IO Timing Modes for details.
  [3:0] VIN1A_D23_MUXMODE rw
    0=VIN1A_D23; 1=VIN1B_D0; 4=VOUT3_D0; 6=VIN3A_D7; 9=KBD_COL8; 10=PR1_EDIO_DATA_IN7; 11=PR1_EDIO_DATA_OUT7; 12=PR1_PRU0_GPI20; 13=PR1_PRU0_GPO20; 14=GPIO3_27; 15=DRIVER OFF
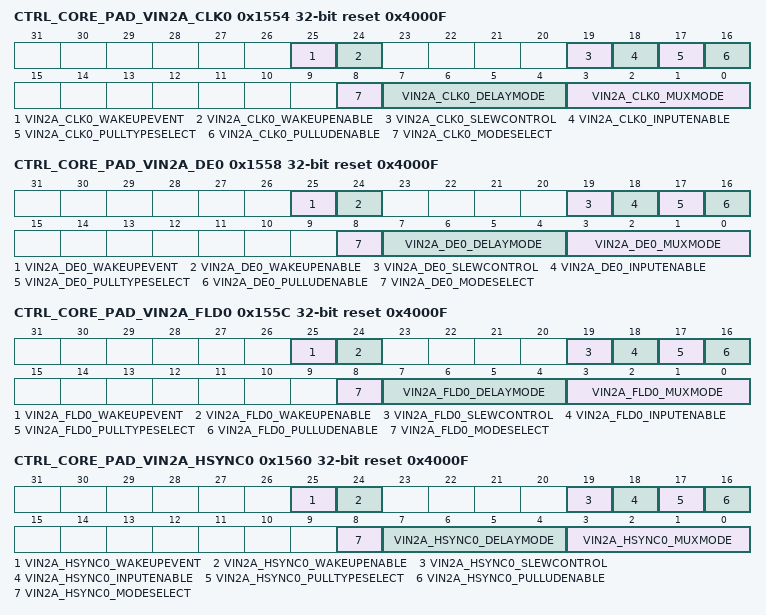
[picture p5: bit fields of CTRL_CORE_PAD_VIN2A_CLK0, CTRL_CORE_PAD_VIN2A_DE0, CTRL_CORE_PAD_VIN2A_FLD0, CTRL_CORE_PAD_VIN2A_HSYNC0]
0x1554 CTRL_CORE_PAD_VIN2A_CLK0 reset 0x4000F
  [25] VIN2A_CLK0_WAKEUPEVENT ro
    values as CTRL_CORE_PAD_VIN1A_D4.VIN1A_D4_WAKEUPEVENT
  [24] VIN2A_CLK0_WAKEUPENABLE rw
    0=DISABLE (Wakeup is disabled); 1=ENABLE (Wakeup is enabled)
  [19] VIN2A_CLK0_SLEWCONTROL rw
    values as CTRL_CORE_PAD_VIN1A_D4.VIN1A_D4_SLEWCONTROL
  [18] VIN2A_CLK0_INPUTENABLE rw
    values as CTRL_CORE_PAD_VIN1A_D4.VIN1A_D4_INPUTENABLE
  [17] VIN2A_CLK0_PULLTYPESELECT rw
    values as CTRL_CORE_PAD_VIN1A_D4.VIN1A_D4_PULLTYPESELECT
  [16] VIN2A_CLK0_PULLUDENABLE rw
    values as CTRL_CORE_PAD_VIN1A_D4.VIN1A_D4_PULLUDENABLE
  [8] VIN2A_CLK0_MODESELECT rw — Selects between the Default IO Timing Mode and a Virtual or Manual IO Timing Mode. Refer to the device Data Manual for definition of the required settings for a given mode of operation. When this bit is 0b1, a Virtual IO Timing Mode can be selected via the DELAYMODE field of this register, as described in, Virtual IO Timing Modes. Manual IO Timing Modes are selected via the procedure described in , Manual IO Timing Modes.
    values as CTRL_CORE_PAD_VIN1A_D4.VIN1A_D4_MODESELECT
  [7:4] VIN2A_CLK0_DELAYMODE rw — This bit field selects the Virtual Timing Mode used when the MODESELECT bit is set to 0b1. See, Virtual IO Timing Modes for details.
  [3:0] VIN2A_CLK0_MUXMODE rw
    0=VIN2A_CLK0; 4=VOUT2_FLD; 5=EMU5; 9=KBD_ROW0; 10=EQEP1A_IN; 12=PR1_EDIO_DATA_IN0; 13=PR1_EDIO_DATA_OUT0; 14=GPIO3_28; 15=DRIVER OFF
0x1558 CTRL_CORE_PAD_VIN2A_DE0 reset 0x4000F
  [25] VIN2A_DE0_WAKEUPEVENT ro
    values as CTRL_CORE_PAD_VIN1A_D4.VIN1A_D4_WAKEUPEVENT
  [24] VIN2A_DE0_WAKEUPENABLE rw
    0=DISABLE (Wakeup is disabled); 1=ENABLE (Wakeup is enabled)
  [19] VIN2A_DE0_SLEWCONTROL rw
    values as CTRL_CORE_PAD_VIN1A_D4.VIN1A_D4_SLEWCONTROL
  [18] VIN2A_DE0_INPUTENABLE rw
    values as CTRL_CORE_PAD_VIN1A_D4.VIN1A_D4_INPUTENABLE
  [17] VIN2A_DE0_PULLTYPESELECT rw
    values as CTRL_CORE_PAD_VIN1A_D4.VIN1A_D4_PULLTYPESELECT
  [16] VIN2A_DE0_PULLUDENABLE rw
    values as CTRL_CORE_PAD_VIN1A_D4.VIN1A_D4_PULLUDENABLE
  [8] VIN2A_DE0_MODESELECT rw — Selects between the Default IO Timing Mode and a Virtual or Manual IO Timing Mode. Refer to the device Data Manual for definition of the required settings for a given mode of operation. When this bit is 0b1, a Virtual IO Timing Mode can be selected via the DELAYMODE field of this register, as described in, Virtual IO Timing Modes. Manual IO Timing Modes are selected via the procedure described in , Manual IO Timing Modes.
    values as CTRL_CORE_PAD_VIN1A_D4.VIN1A_D4_MODESELECT
  [7:4] VIN2A_DE0_DELAYMODE rw — This bit field selects the Virtual Timing Mode used when the MODESELECT bit is set to 0b1. See, Virtual IO Timing Modes for details.
  [3:0] VIN2A_DE0_MUXMODE rw
    0=VIN2A_DE0; 1=VIN2A_FLD0; 2=VIN2B_FLD1; 3=VIN2B_DE1; 4=VOUT2_DE; 5=EMU6; 9=KBD_ROW1; 10=EQEP1B_IN; 12=PR1_EDIO_DATA_IN1; 13=PR1_EDIO_DATA_OUT1; 14=GPIO3_29; 15=DRIVER OFF
0x155C CTRL_CORE_PAD_VIN2A_FLD0 reset 0x4000F
  [25] VIN2A_FLD0_WAKEUPEVENT ro
    values as CTRL_CORE_PAD_VIN1A_D4.VIN1A_D4_WAKEUPEVENT
  [24] VIN2A_FLD0_WAKEUPENABLE rw
    0=DISABLE (Wakeup is disabled); 1=ENABLE (Wakeup is enabled)
  [19] VIN2A_FLD0_SLEWCONTROL rw
    values as CTRL_CORE_PAD_VIN1A_D4.VIN1A_D4_SLEWCONTROL
  [18] VIN2A_FLD0_INPUTENABLE rw
    values as CTRL_CORE_PAD_VIN1A_D4.VIN1A_D4_INPUTENABLE
  [17] VIN2A_FLD0_PULLTYPESELECT rw
    values as CTRL_CORE_PAD_VIN1A_D4.VIN1A_D4_PULLTYPESELECT
  [16] VIN2A_FLD0_PULLUDENABLE rw
    values as CTRL_CORE_PAD_VIN1A_D4.VIN1A_D4_PULLUDENABLE
  [8] VIN2A_FLD0_MODESELECT rw — Selects between the Default IO Timing Mode and a Virtual or Manual IO Timing Mode. Refer to the device Data Manual for definition of the required settings for a given mode of operation. When this bit is 0b1, a Virtual IO Timing Mode can be selected via the DELAYMODE field of this register, as described in, Virtual IO Timing Modes. Manual IO Timing Modes are selected via the procedure described in , Manual IO Timing Modes.
    values as CTRL_CORE_PAD_VIN1A_D4.VIN1A_D4_MODESELECT
  [7:4] VIN2A_FLD0_DELAYMODE rw — This bit field selects the Virtual Timing Mode used when the MODESELECT bit is set to 0b1. See, Virtual IO Timing Modes for details.
  [3:0] VIN2A_FLD0_MUXMODE rw
    0=VIN2A_FLD0; 2=VIN2B_CLK1; 4=VOUT2_CLK; 5=EMU7; 10=EQEP1_INDEX; 12=PR1_EDIO_DATA_IN2; 13=PR1_EDIO_DATA_OUT2; 14=GPIO3_30; 15=DRIVER OFF
0x1560 CTRL_CORE_PAD_VIN2A_HSYNC0 reset 0x4000F
  [25] VIN2A_HSYNC0_WAKEUPEVENT ro
    values as CTRL_CORE_PAD_VIN1A_D4.VIN1A_D4_WAKEUPEVENT
  [24] VIN2A_HSYNC0_WAKEUPENABLE rw
    0=DISABLE (Wakeup is disabled); 1=ENABLE (Wakeup is enabled)
  [19] VIN2A_HSYNC0_SLEWCONTROL rw
    values as CTRL_CORE_PAD_VIN1A_D4.VIN1A_D4_SLEWCONTROL
  [18] VIN2A_HSYNC0_INPUTENABLE rw
    values as CTRL_CORE_PAD_VIN1A_D4.VIN1A_D4_INPUTENABLE
  [17] VIN2A_HSYNC0_PULLTYPESELECT rw
    values as CTRL_CORE_PAD_VIN1A_D4.VIN1A_D4_PULLTYPESELECT
  [16] VIN2A_HSYNC0_PULLUDENABLE rw
    values as CTRL_CORE_PAD_VIN1A_D4.VIN1A_D4_PULLUDENABLE
  [8] VIN2A_HSYNC0_MODESELECT rw — Selects between the Default IO Timing Mode and a Virtual or Manual IO Timing Mode. Refer to the device Data Manual for definition of the required settings for a given mode of operation. When this bit is 0b1, a Virtual IO Timing Mode can be selected via the DELAYMODE field of this register, as described in, Virtual IO Timing Modes. Manual IO Timing Modes are selected via the procedure described in , Manual IO Timing Modes.
    values as CTRL_CORE_PAD_VIN1A_D4.VIN1A_D4_MODESELECT
  [7:4] VIN2A_HSYNC0_DELAYMODE rw — This bit field selects the Virtual Timing Mode used when the MODESELECT bit is set to 0b1. See, Virtual IO Timing Modes for details.
  [3:0] VIN2A_HSYNC0_MUXMODE rw
    0=VIN2A_HSYNC0; 3=VIN2B_HSYNC1; 4=VOUT2_HSYNC; 5=EMU8; 7=UART9_RXD; 8=SPI4_SCLK; 9=KBD_ROW2; 10=EQEP1_STROBE; 11=PR1_UART0_CTS_N; 12=PR1_EDIO_DATA_IN3; 13=PR1_EDIO_DATA_OUT3; 14=GPIO3_31; 15=DRIVER OFF
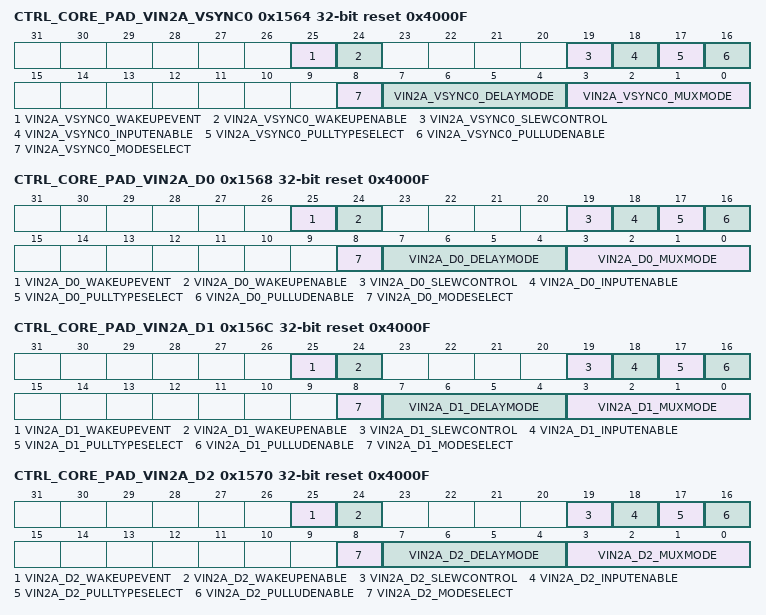
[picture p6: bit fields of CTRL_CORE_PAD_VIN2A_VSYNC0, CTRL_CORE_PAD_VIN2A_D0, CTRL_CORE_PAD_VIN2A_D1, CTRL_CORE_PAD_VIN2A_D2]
0x1564 CTRL_CORE_PAD_VIN2A_VSYNC0 reset 0x4000F
  [25] VIN2A_VSYNC0_WAKEUPEVENT ro
    values as CTRL_CORE_PAD_VIN1A_D4.VIN1A_D4_WAKEUPEVENT
  [24] VIN2A_VSYNC0_WAKEUPENABLE rw
    0=DISABLE (Wakeup is disabled); 1=ENABLE (Wakeup is enabled)
  [19] VIN2A_VSYNC0_SLEWCONTROL rw
    values as CTRL_CORE_PAD_VIN1A_D4.VIN1A_D4_SLEWCONTROL
  [18] VIN2A_VSYNC0_INPUTENABLE rw
    values as CTRL_CORE_PAD_VIN1A_D4.VIN1A_D4_INPUTENABLE
  [17] VIN2A_VSYNC0_PULLTYPESELECT rw
    values as CTRL_CORE_PAD_VIN1A_D4.VIN1A_D4_PULLTYPESELECT
  [16] VIN2A_VSYNC0_PULLUDENABLE rw
    values as CTRL_CORE_PAD_VIN1A_D4.VIN1A_D4_PULLUDENABLE
  [8] VIN2A_VSYNC0_MODESELECT rw — Selects between the Default IO Timing Mode and a Virtual or Manual IO Timing Mode. Refer to the device Data Manual for definition of the required settings for a given mode of operation. When this bit is 0b1, a Virtual IO Timing Mode can be selected via the DELAYMODE field of this register, as described in, Virtual IO Timing Modes. Manual IO Timing Modes are selected via the procedure described in , Manual IO Timing Modes.
    values as CTRL_CORE_PAD_VIN1A_D4.VIN1A_D4_MODESELECT
  [7:4] VIN2A_VSYNC0_DELAYMODE rw — This bit field selects the Virtual Timing Mode used when the MODESELECT bit is set to 0b1. See, Virtual IO Timing Modes for details.
  [3:0] VIN2A_VSYNC0_MUXMODE rw
    0=VIN2A_VSYNC0; 3=VIN2B_VSYNC1; 4=VOUT2_VSYNC; 5=EMU9; 7=UART9_TXD; 8=SPI4_D1; 9=KBD_ROW3; 10=EHRPWM1A; 11=PR1_UART0_RTS_N; 12=PR1_EDIO_DATA_IN4; 13=PR1_EDIO_DATA_OUT4; 14=GPIO4_0; 15=DRIVER OFF
0x1568 CTRL_CORE_PAD_VIN2A_D0 reset 0x4000F
  [25] VIN2A_D0_WAKEUPEVENT ro
    values as CTRL_CORE_PAD_VIN1A_D4.VIN1A_D4_WAKEUPEVENT
  [24] VIN2A_D0_WAKEUPENABLE rw
    0=DISABLE (Wakeup is disabled); 1=ENABLE (Wakeup is enabled)
  [19] VIN2A_D0_SLEWCONTROL rw
    values as CTRL_CORE_PAD_VIN1A_D4.VIN1A_D4_SLEWCONTROL
  [18] VIN2A_D0_INPUTENABLE rw
    values as CTRL_CORE_PAD_VIN1A_D4.VIN1A_D4_INPUTENABLE
  [17] VIN2A_D0_PULLTYPESELECT rw
    values as CTRL_CORE_PAD_VIN1A_D4.VIN1A_D4_PULLTYPESELECT
  [16] VIN2A_D0_PULLUDENABLE rw
    values as CTRL_CORE_PAD_VIN1A_D4.VIN1A_D4_PULLUDENABLE
  [8] VIN2A_D0_MODESELECT rw — Selects between the Default IO Timing Mode and a Virtual or Manual IO Timing Mode. Refer to the device Data Manual for definition of the required settings for a given mode of operation. When this bit is 0b1, a Virtual IO Timing Mode can be selected via the DELAYMODE field of this register, as described in, Virtual IO Timing Modes. Manual IO Timing Modes are selected via the procedure described in , Manual IO Timing Modes.
    values as CTRL_CORE_PAD_VIN1A_D4.VIN1A_D4_MODESELECT
  [7:4] VIN2A_D0_DELAYMODE rw — This bit field selects the Virtual Timing Mode used when the MODESELECT bit is set to 0b1. See, Virtual IO Timing Modes for details.
  [3:0] VIN2A_D0_MUXMODE rw
    0=VIN2A_D0; 4=VOUT2_D23; 5=EMU10; 7=UART9_CTSN; 8=SPI4_D0; 9=KBD_ROW4; 10=EHRPWM1B; 11=PR1_UART0_RXD; 12=PR1_EDIO_DATA_IN5; 13=PR1_EDIO_DATA_OUT5; 14=GPIO4_1; 15=DRIVER OFF
0x156C CTRL_CORE_PAD_VIN2A_D1 reset 0x4000F
  [25] VIN2A_D1_WAKEUPEVENT ro
    values as CTRL_CORE_PAD_VIN1A_D4.VIN1A_D4_WAKEUPEVENT
  [24] VIN2A_D1_WAKEUPENABLE rw
    0=DISABLE (Wakeup is disabled); 1=ENABLE (Wakeup is enabled)
  [19] VIN2A_D1_SLEWCONTROL rw
    values as CTRL_CORE_PAD_VIN1A_D4.VIN1A_D4_SLEWCONTROL
  [18] VIN2A_D1_INPUTENABLE rw
    values as CTRL_CORE_PAD_VIN1A_D4.VIN1A_D4_INPUTENABLE
  [17] VIN2A_D1_PULLTYPESELECT rw
    values as CTRL_CORE_PAD_VIN1A_D4.VIN1A_D4_PULLTYPESELECT
  [16] VIN2A_D1_PULLUDENABLE rw
    values as CTRL_CORE_PAD_VIN1A_D4.VIN1A_D4_PULLUDENABLE
  [8] VIN2A_D1_MODESELECT rw — Selects between the Default IO Timing Mode and a Virtual or Manual IO Timing Mode. Refer to the device Data Manual for definition of the required settings for a given mode of operation. When this bit is 0b1, a Virtual IO Timing Mode can be selected via the DELAYMODE field of this register, as described in, Virtual IO Timing Modes. Manual IO Timing Modes are selected via the procedure described in , Manual IO Timing Modes.
    values as CTRL_CORE_PAD_VIN1A_D4.VIN1A_D4_MODESELECT
  [7:4] VIN2A_D1_DELAYMODE rw — This bit field selects the Virtual Timing Mode used when the MODESELECT bit is set to 0b1. See, Virtual IO Timing Modes for details.
  [3:0] VIN2A_D1_MUXMODE rw
    0=VIN2A_D1; 4=VOUT2_D22; 5=EMU11; 7=UART9_RTSN; 8=SPI4_CS0; 9=KBD_ROW5; 10=EHRPWM1_TRIPZONE_INPUT; 11=PR1_UART0_TXD; 12=PR1_EDIO_DATA_IN6; 13=PR1_EDIO_DATA_OUT6; 14=GPIO4_2; 15=DRIVER OFF
0x1570 CTRL_CORE_PAD_VIN2A_D2 reset 0x4000F
  [25] VIN2A_D2_WAKEUPEVENT ro
    values as CTRL_CORE_PAD_VIN1A_D4.VIN1A_D4_WAKEUPEVENT
  [24] VIN2A_D2_WAKEUPENABLE rw
    0=DISABLE (Wakeup is disabled); 1=ENABLE (Wakeup is enabled)
  [19] VIN2A_D2_SLEWCONTROL rw
    values as CTRL_CORE_PAD_VIN1A_D4.VIN1A_D4_SLEWCONTROL
  [18] VIN2A_D2_INPUTENABLE rw
    values as CTRL_CORE_PAD_VIN1A_D4.VIN1A_D4_INPUTENABLE
  [17] VIN2A_D2_PULLTYPESELECT rw
    values as CTRL_CORE_PAD_VIN1A_D4.VIN1A_D4_PULLTYPESELECT
  [16] VIN2A_D2_PULLUDENABLE rw
    values as CTRL_CORE_PAD_VIN1A_D4.VIN1A_D4_PULLUDENABLE
  [8] VIN2A_D2_MODESELECT rw — Selects between the Default IO Timing Mode and a Virtual or Manual IO Timing Mode. Refer to the device Data Manual for definition of the required settings for a given mode of operation. When this bit is 0b1, a Virtual IO Timing Mode can be selected via the DELAYMODE field of this register, as described in, Virtual IO Timing Modes. Manual IO Timing Modes are selected via the procedure described in , Manual IO Timing Modes.
    values as CTRL_CORE_PAD_VIN1A_D4.VIN1A_D4_MODESELECT
  [7:4] VIN2A_D2_DELAYMODE rw — This bit field selects the Virtual Timing Mode used when the MODESELECT bit is set to 0b1. See, Virtual IO Timing Modes for details.
  [3:0] VIN2A_D2_MUXMODE rw
    0=VIN2A_D2; 4=VOUT2_D21; 5=EMU12; 8=UART10_RXD; 9=KBD_ROW6; 10=ECAP1_IN_PWM1_OUT; 11=PR1_ECAP0_ECAP_CAPIN_APWM_O; 12=PR1_EDIO_DATA_IN7; 13=PR1_EDIO_DATA_OUT7; 14=GPIO4_3; 15=DRIVER OFF
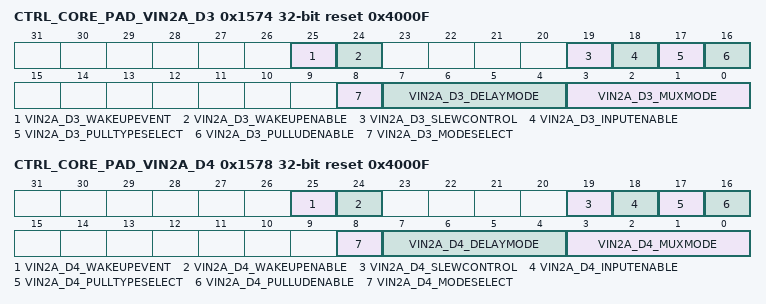
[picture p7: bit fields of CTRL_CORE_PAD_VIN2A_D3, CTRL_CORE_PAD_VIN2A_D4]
0x1574 CTRL_CORE_PAD_VIN2A_D3 reset 0x4000F
  [25] VIN2A_D3_WAKEUPEVENT ro
    values as CTRL_CORE_PAD_VIN1A_D4.VIN1A_D4_WAKEUPEVENT
  [24] VIN2A_D3_WAKEUPENABLE rw
    0=DISABLE (Wakeup is disabled); 1=ENABLE (Wakeup is enabled)
  [19] VIN2A_D3_SLEWCONTROL rw
    values as CTRL_CORE_PAD_VIN1A_D4.VIN1A_D4_SLEWCONTROL
  [18] VIN2A_D3_INPUTENABLE rw
    values as CTRL_CORE_PAD_VIN1A_D4.VIN1A_D4_INPUTENABLE
  [17] VIN2A_D3_PULLTYPESELECT rw
    values as CTRL_CORE_PAD_VIN1A_D4.VIN1A_D4_PULLTYPESELECT
  [16] VIN2A_D3_PULLUDENABLE rw
    values as CTRL_CORE_PAD_VIN1A_D4.VIN1A_D4_PULLUDENABLE
  [8] VIN2A_D3_MODESELECT rw — Selects between the Default IO Timing Mode and a Virtual or Manual IO Timing Mode. Refer to the device Data Manual for definition of the required settings for a given mode of operation. When this bit is 0b1, a Virtual IO Timing Mode can be selected via the DELAYMODE field of this register, as described in, Virtual IO Timing Modes. Manual IO Timing Modes are selected via the procedure described in , Manual IO Timing Modes.
    values as CTRL_CORE_PAD_VIN1A_D4.VIN1A_D4_MODESELECT
  [7:4] VIN2A_D3_DELAYMODE rw — This bit field selects the Virtual Timing Mode used when the MODESELECT bit is set to 0b1. See, Virtual IO Timing Modes for details.
  [3:0] VIN2A_D3_MUXMODE rw
    0=VIN2A_D3; 4=VOUT2_D20; 5=EMU13; 8=UART10_TXD; 9=KBD_COL0; 10=EHRPWM1_SYNCI; 11=PR1_EDC_LATCH0_IN; 12=PR1_PRU1_GPI0; 13=PR1_PRU1_GPO0; 14=GPIO4_4; 15=DRIVER OFF
0x1578 CTRL_CORE_PAD_VIN2A_D4 reset 0x4000F
  [25] VIN2A_D4_WAKEUPEVENT ro
    values as CTRL_CORE_PAD_VIN1A_D4.VIN1A_D4_WAKEUPEVENT
  [24] VIN2A_D4_WAKEUPENABLE rw
    0=DISABLE (Wakeup is disabled); 1=ENABLE (Wakeup is enabled)
  [19] VIN2A_D4_SLEWCONTROL rw
    values as CTRL_CORE_PAD_VIN1A_D4.VIN1A_D4_SLEWCONTROL
  [18] VIN2A_D4_INPUTENABLE rw
    values as CTRL_CORE_PAD_VIN1A_D4.VIN1A_D4_INPUTENABLE
  [17] VIN2A_D4_PULLTYPESELECT rw
    values as CTRL_CORE_PAD_VIN1A_D4.VIN1A_D4_PULLTYPESELECT
  [16] VIN2A_D4_PULLUDENABLE rw
    values as CTRL_CORE_PAD_VIN1A_D4.VIN1A_D4_PULLUDENABLE
  [8] VIN2A_D4_MODESELECT rw — Selects between the Default IO Timing Mode and a Virtual or Manual IO Timing Mode. Refer to the device Data Manual for definition of the required settings for a given mode of operation. When this bit is 0b1, a Virtual IO Timing Mode can be selected via the DELAYMODE field of this register, as described in, Virtual IO Timing Modes. Manual IO Timing Modes are selected via the procedure described in , Manual IO Timing Modes.
    values as CTRL_CORE_PAD_VIN1A_D4.VIN1A_D4_MODESELECT
  [7:4] VIN2A_D4_DELAYMODE rw — This bit field selects the Virtual Timing Mode used when the MODESELECT bit is set to 0b1. See, Virtual IO Timing Modes for details.
  [3:0] VIN2A_D4_MUXMODE rw
    0=VIN2A_D4; 4=VOUT2_D19; 5=EMU14; 8=UART10_CTSN; 9=KBD_COL1; 10=EHRPWM1_SYNCO; 11=PR1_EDC_SYNC0_OUT; 12=PR1_PRU1_GPI1; 13=PR1_PRU1_GPO1; 14=GPIO4_5; 15=DRIVER OFF
